# CH32X315 register map
Vendor: WCH Ltd.; File version: 1.1
Registers are 32-bit, read-write, reset 0x0 unless marked. A register's access mark holds for its fields unless they carry their own. Offsets are from the block's base; [hi:lo] are bit positions; lines under a group give offsets from that group; {n}, {i} and the like mark numbered series.

## ADC1 — Analog to digital converter
Base 0x40012400
Same registers: ADC2 0x40012800, ADC3 0x40013C00, ADC4 0x40014000
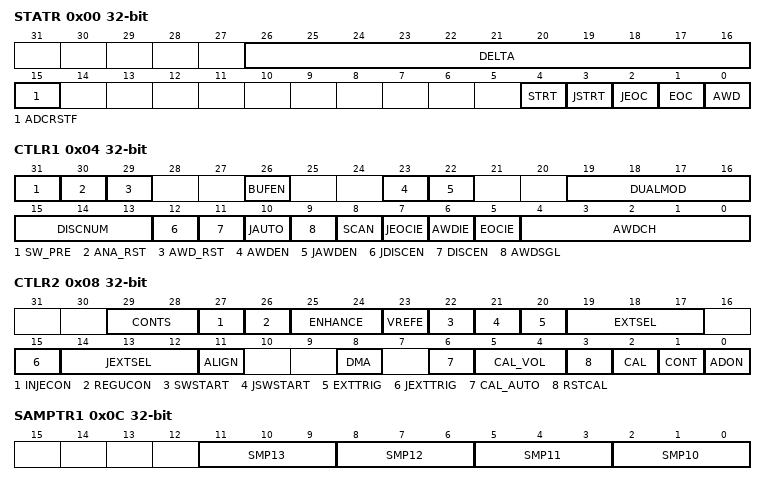
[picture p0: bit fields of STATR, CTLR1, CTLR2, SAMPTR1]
0x00 STATR — status register
  [26:16] DELTA — calibration deviation value
  [15] ADCRSTF — ADC reset flag
  [4] STRT — Regular channel start flag
  [3] JSTRT — Injected channel start flag
  [2] JEOC — Injected channel end of conversion
  [1] EOC — Regular channel end of conversion
  [0] AWD — Analog watchdog flag
0x04 CTLR1 — control register 1/TKEY_V_CTLR
  [31] SW_PRE — Channel pre-handoff is closed
  [30] ANA_RST — simulation module reset enabled
  [29] AWD_RST — ADC watchdog reset enable
  [26] BUFEN — ADC buffer enable
  [23] AWDEN — Analog watchdog enable on regular channels
  [22] JAWDEN — Analog watchdog enable on injected channels
  [19:16] DUALMOD — DOUBLE_MODE enable
  [15:13] DISCNUM — Discontinuous mode channel count
  [12] JDISCEN — Discontinuous mode on injected channels
  [11] DISCEN — Discontinuous mode on regular channels
  [10] JAUTO — Automatic injected group conversion
  [9] AWDSGL — Enable the watchdog on a single channel in scan mode
  [8] SCAN — Scan mode enable
  [7] JEOCIE — Interrupt enable for injected channels
  [6] AWDIE — Analog watchdog interrupt enable
  [5] EOCIE — Interrupt enable for EOC
  [4:0] AWDCH — Analog watchdog channel select bits
0x08 CTLR2 — control register 2
  [29:28] CONTS — ADC preamplifier selection bit
  [27] INJECON — inject channel cascading enable bit
  [26] REGUCON — rule channel cascade enable bit
  [25:24] ENHANCE — enhancement mode configuration bit
  [23] VREFE — internal voltage channel enable bit
  [22] SWSTART — Start conversion of regular channels
  [21] JSWSTART — Start conversion of injected channels
  [20] EXTTRIG — External trigger conversion mode for regular channels
  [19:17] EXTSEL — External event select for regular group
  [15] JEXTTRIG — External trigger conversion mode for injected channels
  [14:12] JEXTSEL — External event select for injected group
  [11] ALIGN — Data alignment
  [8] DMA — Direct memory access mode
  [6] CAL_AUTO — the hardware automatic calibration
  [5:4] CAL_VOL — calibration voltage configuration
  [3] RSTCAL — Reset calibration
  [2] CAL — A/D calibration
  [1] CONT — Continuous conversion
  [0] ADON — A/D converter ON / OFF
0x0C SAMPTR1 — sample time register 1
  [3n-28:3n-30] SMP{n} (n=10..13) — Channel {n} sample time selection
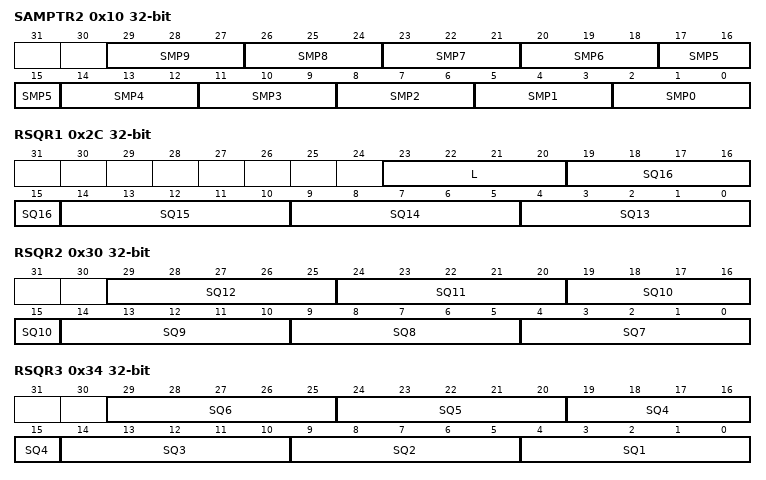
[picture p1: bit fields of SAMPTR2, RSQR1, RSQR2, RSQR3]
0x10 SAMPTR2 — sample time register 2
  [3n+2:3n] SMP{n} (n=0..9) — Channel {n} sample time selection
{0x10+4i} IOFR{i} (i=1..4) — injected channel data offset register x
  [14:0] JOFFSET{i} — Data offset for injected channel x
0x24 WDHTR reset 0xFFF — watchdog higher threshold register
  [14:0] HT — Analog watchdog higher threshold
0x28 WDLTR — watchdog lower threshold register
  [14:0] LT — Analog watchdog lower threshold
0x2C RSQR1 — regular sequence register 1
  [23:20] L — Regular channel sequence length
  [5n-61:5n-65] SQ{n} (n=13..16) — {n}th conversion in regular sequence
0x30 RSQR2 — regular sequence register 2
  [5n-31:5n-35] SQ{n} (n=7..12) — {n}th conversion in regular sequence
0x34 RSQR3 — regular sequence register 3
  [29:25] SQ6 — 6th conversion in regular sequence
  [24:20] SQ5 — 5th conversion in regular sequence
  [19:15] SQ4 — 4th conversion in regular sequence
  [14:10] SQ3 — 3rd conversion in regular sequence
  [9:5] SQ2 — 2nd conversion in regular sequence
  [4:0] SQ1 — 1st conversion in regular sequence
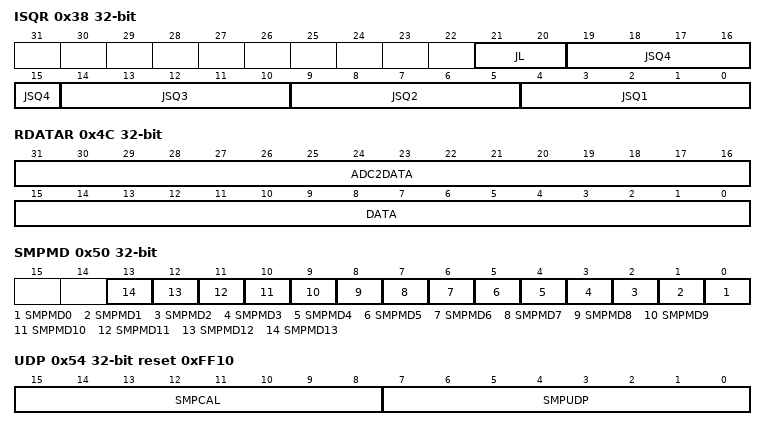
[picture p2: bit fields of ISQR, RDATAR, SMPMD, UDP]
0x38 ISQR — injected sequence register
  [21:20] JL — Injected sequence length
  [19:15] JSQ4 — 4th conversion in injected sequence
  [14:10] JSQ3 — 3rd conversion in injected sequence
  [9:5] JSQ2 — 2nd conversion in injected sequence
  [4:0] JSQ1 — 1st conversion in injected sequence
{0x38+4i} IDATAR{i} ro (i=1..4) — injected data register x
  [15:0] JDATA — Injected data
0x4C RDATAR ro — regular data register
  [31:16] ADC2DATA — converter data
  [15:0] DATA — Regular data
0x50 SMPMD — ADC sampling time register
  [n] SMPMD{n} (n=0..13) — channel sampling mode configuration
0x54 UDP reset 0xFF10 — ADC programmable sampling time register
  [15:8] SMPCAL — calibration channel sampling time
  [7:0] SMPUDP — user programmable sampling time
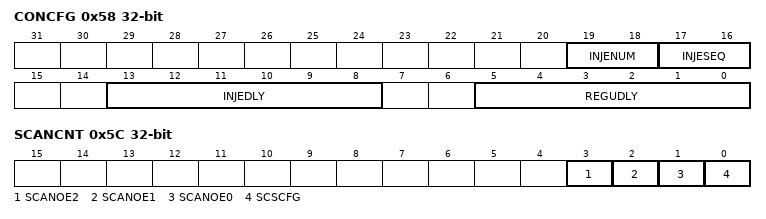
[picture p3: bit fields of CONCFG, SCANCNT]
0x58 CONCFG — ADC cascade configure register
  [19:18] INJENUM — inject trigger to configure the exchange cycle period
  [17:16] INJESEQ — effective injection of trigger sequence number configuration
  [13:8] INJEDLY — injection of channel-level cascading trigger delay
  [5:0] REGUDLY — rule channel cascade trigger delay
0x5C SCANCNT — ADC scanning count configuration register
  [3] SCANOE2 — Output enable bit of the scanning cycle counter bit 2
  [2] SCANOE1 — Output enable bit of the scanning cycle counter bit 1
  [1] SCANOE0 — Output enable bit of the scanning cycle counter bit 0
  [0] SCSCFG — scan channel source configuration bit
